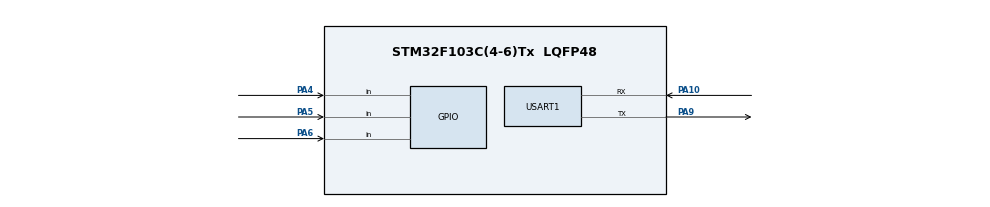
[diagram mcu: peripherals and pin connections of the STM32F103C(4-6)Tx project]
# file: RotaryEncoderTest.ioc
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Mcu.Family=STM32F1
Mcu.Name=STM32F103C(4-6)Tx
Mcu.Package=LQFP48
NVIC.PriorityGroup=NVIC_PRIORITYGROUP_4
PA10.Mode=Asynchronous
PA10.Signal=USART1_RX
PA4.Signal=GPIO_Input
PA5.Signal=GPIO_Input
PA6.Signal=GPIO_Input
PA9.Mode=Asynchronous
PA9.Signal=USART1_TX
ProjectManager.HeapSize=0x200
ProjectManager.StackSize=0x400
ProjectManager.TargetToolchain=STM32CubeIDE
RCC.APB1Freq_Value=8000000
RCC.APB2Freq_Value=8000000
USART1.VirtualMode=VM_ASYNC
VP_RTC_VS_RTC_Activate.Mode=RTC_Enabled
VP_SYS_VS_ND.Mode=No_Debug
board=custom

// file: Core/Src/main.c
/* USER CODE BEGIN Header */
/**
  ******************************************************************************
  * @file           : main.c
  * @brief          : Main program body
  ******************************************************************************
  * @attention
  *
  * <h2><center>&copy; Copyright (c) 2020 STMicroelectronics.
  * All rights reserved.</center></h2>
  *
  * This software component is licensed by ST under BSD 3-Clause license,
  * the "License"; You may not use this file except in compliance with the
  * License. You may obtain a copy of the License at:
  *                        opensource.org/licenses/BSD-3-Clause
  *
  ******************************************************************************
  */
/* USER CODE END Header */
#include "main.h"
#include <stdio.h>
#include <string.h>

/* USER CODE BEGIN PM */
#define ROT_SW  GPIO_PIN_4
#define ROT_DT  GPIO_PIN_5
#define ROT_CLK GPIO_PIN_6
/* USER CODE END PM */

RTC_HandleTypeDef hrtc;

UART_HandleTypeDef huart1;

void SystemClock_Config(void);
static void MX_GPIO_Init(void);
static void MX_USART1_UART_Init(void);
static void MX_RTC_Init(void);

int main(void)
{
  /* USER CODE BEGIN 1 */
	char msg[20];
	GPIO_PinState clk_current, clk_last,sw_state,dt_state;
	int counter=0;
	RTC_TimeTypeDef t0;

	HAL_RTC_GetTime(&hrtc, &t0, RTC_FORMAT_BIN);
  /* USER CODE END 1 */

  /* MCU Configuration--------------------------------------------------------*/

  /* Reset of all peripherals, Initializes the Flash interface and the Systick. */
  HAL_Init();

  /* Configure the system clock */
  SystemClock_Config();

  /* Initialize all configured peripherals */
  MX_GPIO_Init();
  MX_USART1_UART_Init();
  MX_RTC_Init();
  /* USER CODE BEGIN 2 */
  clk_last = HAL_GPIO_ReadPin(GPIOA, ROT_CLK);
  sprintf(msg, "init!!\r\n");
  HAL_UART_Transmit(&huart1, (uint8_t*)msg, strlen(msg), HAL_MAX_DELAY);
  /* USER CODE END 2 */

  /* Infinite loop */
  while (1)
  {
	  clk_current = HAL_GPIO_ReadPin(GPIOA, ROT_CLK);
	  if(clk_current != clk_last && clk_current == GPIO_PIN_SET)
	  {
		  dt_state = HAL_GPIO_ReadPin(GPIOA,ROT_DT);
		  if(dt_state != clk_current)
		  {
			  counter--;
		  }
		  else
		  {
			  counter++;
		  }
		  sprintf(msg, "%d\r\n", counter);
		  HAL_UART_Transmit(&huart1, (uint8_t*)msg, strlen(msg), HAL_MAX_DELAY);
	  }
	  clk_last = clk_current;

	  sw_state = HAL_GPIO_ReadPin(GPIOA,ROT_SW);
	  if(sw_state == GPIO_PIN_RESET)
	  {
		  RTC_TimeTypeDef t1;
		  HAL_RTC_GetTime(&hrtc, &t1, RTC_FORMAT_BIN);

		  uint8_t sec1 = t1.Seconds + t1.Minutes * 60;
		  uint8_t sec0 = t0.Seconds + t0.Minutes * 60;

		  if(sec1 - sec0 > 1)
		  {
			  sprintf(msg, "button press!\r\n");
			  HAL_UART_Transmit(&huart1, (uint8_t*)msg, strlen(msg), HAL_MAX_DELAY);
			  t0 = t1;
		  }

	  }

	  HAL_Delay(1);
  }
}

void SystemClock_Config(void)
{
  RCC_OscInitTypeDef RCC_OscInitStruct = {0};
  RCC_ClkInitTypeDef RCC_ClkInitStruct = {0};
  RCC_PeriphCLKInitTypeDef PeriphClkInit = {0};

  /** Initializes the RCC Oscillators according to the specified parameters
  * in the RCC_OscInitTypeDef structure.
  */
  RCC_OscInitStruct.OscillatorType = RCC_OSCILLATORTYPE_HSI|RCC_OSCILLATORTYPE_LSI;
  RCC_OscInitStruct.HSIState = RCC_HSI_ON;
  RCC_OscInitStruct.HSICalibrationValue = RCC_HSICALIBRATION_DEFAULT;
  RCC_OscInitStruct.LSIState = RCC_LSI_ON;
  RCC_OscInitStruct.PLL.PLLState = RCC_PLL_NONE;
  if (HAL_RCC_OscConfig(&RCC_OscInitStruct) != HAL_OK)
  {
    Error_Handler();
  }
  /** Initializes the CPU, AHB and APB buses clocks
  */
  RCC_ClkInitStruct.ClockType = RCC_CLOCKTYPE_HCLK|RCC_CLOCKTYPE_SYSCLK
                              |RCC_CLOCKTYPE_PCLK1|RCC_CLOCKTYPE_PCLK2;
  RCC_ClkInitStruct.SYSCLKSource = RCC_SYSCLKSOURCE_HSI;
  RCC_ClkInitStruct.AHBCLKDivider = RCC_SYSCLK_DIV1;
  RCC_ClkInitStruct.APB1CLKDivider = RCC_HCLK_DIV1;
  RCC_ClkInitStruct.APB2CLKDivider = RCC_HCLK_DIV1;

  if (HAL_RCC_ClockConfig(&RCC_ClkInitStruct, FLASH_LATENCY_0) != HAL_OK)
  {
    Error_Handler();
  }
  PeriphClkInit.PeriphClockSelection = RCC_PERIPHCLK_RTC;
  PeriphClkInit.RTCClockSelection = RCC_RTCCLKSOURCE_LSI;
  if (HAL_RCCEx_PeriphCLKConfig(&PeriphClkInit) != HAL_OK)
  {
    Error_Handler();
  }
}

static void MX_RTC_Init(void)
{

  /** Initialize RTC Only
  */
  hrtc.Instance = RTC;
  hrtc.Init.AsynchPrediv = RTC_AUTO_1_SECOND;
  hrtc.Init.OutPut = RTC_OUTPUTSOURCE_ALARM;
  if (HAL_RTC_Init(&hrtc) != HAL_OK)
  {
    Error_Handler();
  }

}

static void MX_USART1_UART_Init(void)
{

  huart1.Instance = USART1;
  huart1.Init.BaudRate = 115200;
  huart1.Init.WordLength = UART_WORDLENGTH_8B;
  huart1.Init.StopBits = UART_STOPBITS_1;
  huart1.Init.Parity = UART_PARITY_NONE;
  huart1.Init.Mode = UART_MODE_TX_RX;
  huart1.Init.HwFlowCtl = UART_HWCONTROL_NONE;
  huart1.Init.OverSampling = UART_OVERSAMPLING_16;
  if (HAL_UART_Init(&huart1) != HAL_OK)
  {
    Error_Handler();
  }

}

static void MX_GPIO_Init(void)
{
  GPIO_InitTypeDef GPIO_InitStruct = {0};

  /* GPIO Ports Clock Enable */
  __HAL_RCC_GPIOA_CLK_ENABLE();

  /*Configure GPIO pins : PA4 PA5 PA6 */
  GPIO_InitStruct.Pin = GPIO_PIN_4|GPIO_PIN_5|GPIO_PIN_6;
  GPIO_InitStruct.Mode = GPIO_MODE_INPUT;
  GPIO_InitStruct.Pull = GPIO_NOPULL;
  HAL_GPIO_Init(GPIOA, &GPIO_InitStruct);

}

void Error_Handler(void)
{
  __disable_irq();
  while (1)
  {
  }
}

/************************ (C) COPYRIGHT STMicroelectronics *****END OF FILE****/
